# f280015x_adc_regs register map
Vendor: Texas Instruments
Peripheral module from a debugger description file (folder C2000).
Address unit: 16 bits
Registers are 16-bit, read-write, no defined reset value unless marked. A register's access mark holds for its fields unless they carry their own. Offsets are as the file gives them; lines under a group give offsets from that group; [hi:lo] are bit positions; {n}, {i} and the like mark numbered series; 'fields as' and 'values as' point back to an identical list; <NAME> marks a mode.

## ADC_REGS — ADC Registers
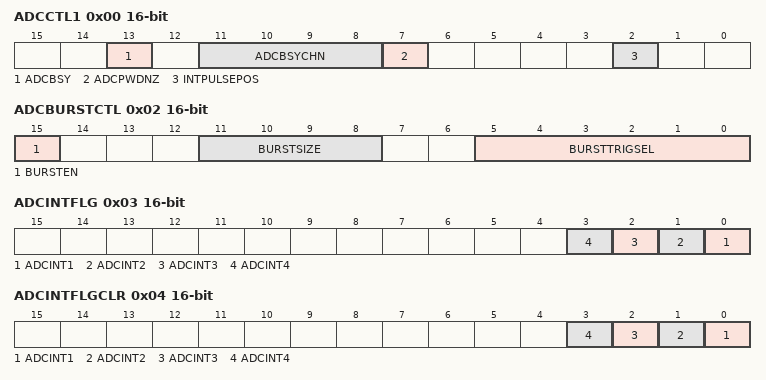
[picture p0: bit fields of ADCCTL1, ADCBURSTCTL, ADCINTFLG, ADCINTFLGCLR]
0x00 ADCCTL1 access per field — ADC Control 1 Register
  [13] ADCBSY ro — ADC Busy
  [11:8] ADCBSYCHN ro — ADC Busy Channel
  [7] ADCPWDNZ rw — ADC Power Down
  [2] INTPULSEPOS rw — ADC Interrupt Pulse Position
0x01 ADCCTL2 — ADC Control 2 Register
  [3:0] PRESCALE — ADC Clock Prescaler
0x02 ADCBURSTCTL — ADC Burst Control Register
  [15] BURSTEN — SOC Burst Mode Enable
  [11:8] BURSTSIZE — SOC Burst Size Select
  [5:0] BURSTTRIGSEL — SOC Burst Trigger Source Select
0x03 ADCINTFLG ro — ADC Interrupt Flag Register
  [n-1] ADCINT{n} (n=1..4) — ADC Interrupt {n} Flag
0x04 ADCINTFLGCLR — ADC Interrupt Flag Clear Register
  [n-1] ADCINT{n} (n=1..4) — ADC Interrupt {n} Flag Clear
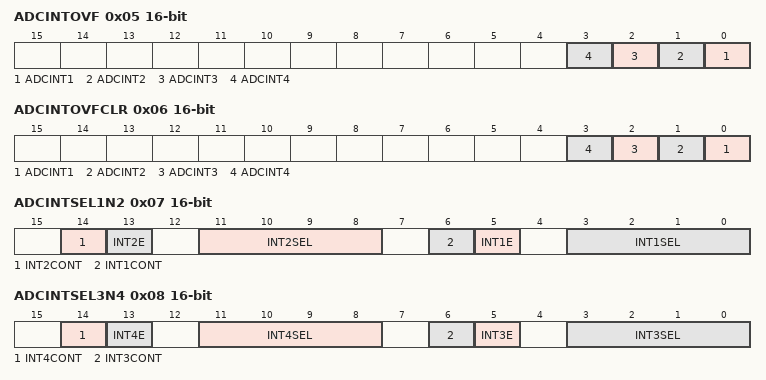
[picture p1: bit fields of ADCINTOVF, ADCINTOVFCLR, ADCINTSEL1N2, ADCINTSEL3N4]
0x05 ADCINTOVF ro — ADC Interrupt Overflow Register
  [n-1] ADCINT{n} (n=1..4) — ADC Interrupt {n} Overflow Flags
0x06 ADCINTOVFCLR — ADC Interrupt Overflow Clear Register
  [n-1] ADCINT{n} (n=1..4) — ADC Interrupt {n} Overflow Clear Bits
0x07 ADCINTSEL1N2 — ADC Interrupt 1 and 2 Selection Register
  [14] INT2CONT — ADCINT2 Continue to Interrupt Mode
  [13] INT2E — ADCINT2 Interrupt Enable
  [11:8] INT2SEL — ADCINT2 EOC Source Select
  [6] INT1CONT — ADCINT1 Continue to Interrupt Mode
  [5] INT1E — ADCINT1 Interrupt Enable
  [3:0] INT1SEL — ADCINT1 EOC Source Select
0x08 ADCINTSEL3N4 — ADC Interrupt 3 and 4 Selection Register
  [14] INT4CONT — ADCINT4 Continue to Interrupt Mode
  [13] INT4E — ADCINT4 Interrupt Enable
  [11:8] INT4SEL — ADCINT4 EOC Source Select
  [6] INT3CONT — ADCINT3 Continue to Interrupt Mode
  [5] INT3E — ADCINT3 Interrupt Enable
  [3:0] INT3SEL — ADCINT3 EOC Source Select
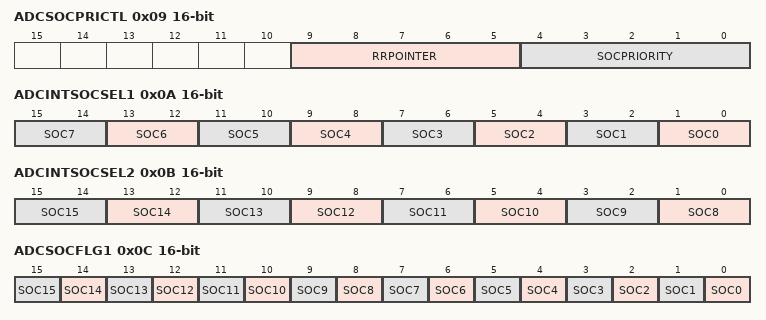
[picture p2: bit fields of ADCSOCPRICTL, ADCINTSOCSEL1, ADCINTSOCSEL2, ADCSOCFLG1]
0x09 ADCSOCPRICTL access per field — ADC SOC Priority Control Register
  [9:5] RRPOINTER ro — Round Robin Pointer
  [4:0] SOCPRIORITY rw
0x0A ADCINTSOCSEL1 — ADC Interrupt SOC Selection 1 Register
  [2n+1:2n] SOC{n} (n=0..7) — SOC{n} ADC Interrupt Trigger Select
0x0B ADCINTSOCSEL2 — ADC Interrupt SOC Selection 2 Register
  [2n-15:2n-16] SOC{n} (n=8..15) — SOC{n} ADC Interrupt Trigger Select
0x0C ADCSOCFLG1 ro — ADC SOC Flag 1 Register
  [n] SOC{n} (n=0..15) — SOC{n} Start of Conversion Flag
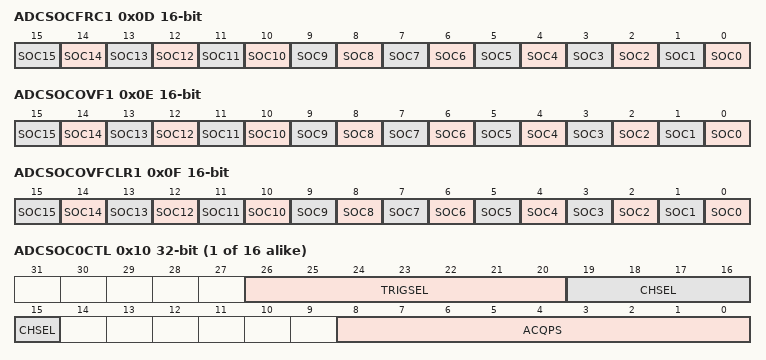
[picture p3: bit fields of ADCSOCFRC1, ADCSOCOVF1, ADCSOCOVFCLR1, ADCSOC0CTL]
0x0D ADCSOCFRC1 — ADC SOC Force 1 Register
  [n] SOC{n} (n=0..15) — SOC{n} Force Start of Conversion Bit
0x0E ADCSOCOVF1 ro — ADC SOC Overflow 1 Register
  [n] SOC{n} (n=0..15) — SOC{n} Start of Conversion Overflow Flag
0x0F ADCSOCOVFCLR1 — ADC SOC Overflow Clear 1 Register
  [n] SOC{n} (n=0..15) — SOC{n} Clear Start of Conversion Overflow Bit
{0x10+2i} ADCSOC{i}CTL 32-bit (i=0..15) — ADC SOC{i} Control Register
  [26:20] TRIGSEL — SOC{i} Trigger Source Select
  [19:15] CHSEL — SOC{i} Channel Select
  [8:0] ACQPS — SOC{i} Acquisition Prescale
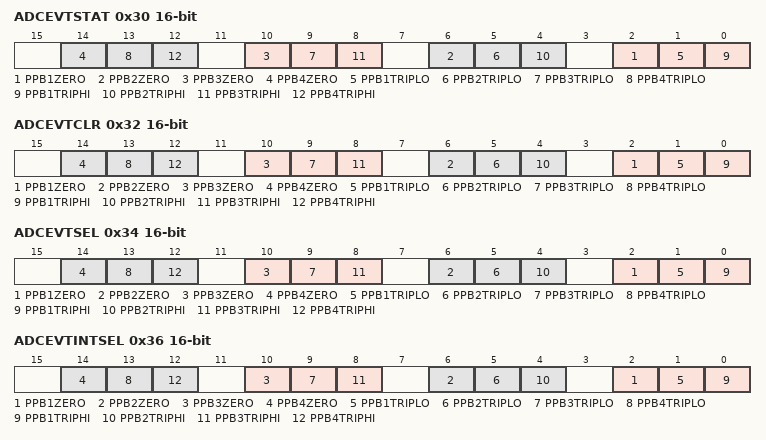
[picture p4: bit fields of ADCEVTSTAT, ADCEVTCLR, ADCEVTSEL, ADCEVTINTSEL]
0x30 ADCEVTSTAT ro — ADC Event Status Register
  [4n-2] PPB{n}ZERO (n=1..4) — Post Processing Block {n} Zero Crossing Flag
  [4n-3] PPB{n}TRIPLO (n=1..4) — Post Processing Block {n} Trip Low Flag
  [4n-4] PPB{n}TRIPHI (n=1..4) — Post Processing Block {n} Trip High Flag
0x32 ADCEVTCLR — ADC Event Clear Register
  [4n-2] PPB{n}ZERO (n=1..4) — Post Processing Block {n} Zero Crossing Clear
  [4n-3] PPB{n}TRIPLO (n=1..4) — Post Processing Block {n} Trip Low Clear
  [4n-4] PPB{n}TRIPHI (n=1..4) — Post Processing Block {n} Trip High Clear
0x34 ADCEVTSEL — ADC Event Selection Register
  [4n-2] PPB{n}ZERO (n=1..4) — Post Processing Block {n} Zero Crossing Event Enable
  [4n-3] PPB{n}TRIPLO (n=1..4) — Post Processing Block {n} Trip Low Event Enable
  [4n-4] PPB{n}TRIPHI (n=1..4) — Post Processing Block {n} Trip High Event Enable
0x36 ADCEVTINTSEL — ADC Event Interrupt Selection Register
  [4n-2] PPB{n}ZERO (n=1..4) — Post Processing Block {n} Zero Crossing Interrupt Enable
  [4n-3] PPB{n}TRIPLO (n=1..4) — Post Processing Block {n} Trip Low Interrupt Enable
  [4n-4] PPB{n}TRIPHI (n=1..4) — Post Processing Block {n} Trip High Interrupt Enable
0x38 ADCOSDETECT — ADC Open and Shorts Detect Register
  [2:0] DETECTCFG — ADC Opens and Shorts Detect Configuration
0x39 ADCCOUNTER ro
  [11:0] FREECOUNT — ADC Free Running Counter Value
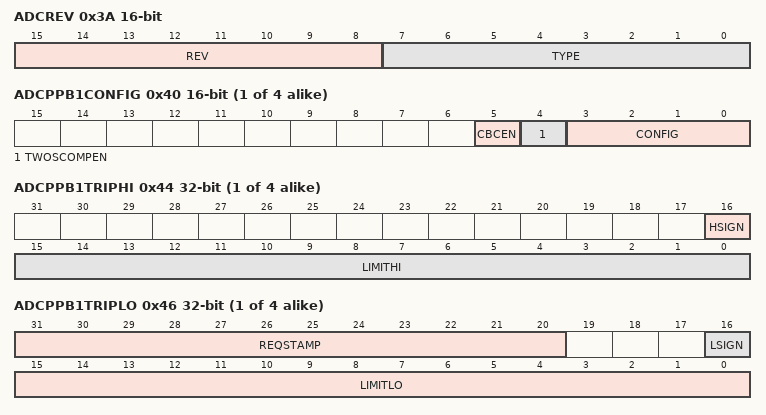
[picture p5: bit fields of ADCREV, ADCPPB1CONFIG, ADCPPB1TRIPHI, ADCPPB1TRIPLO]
0x3A ADCREV ro — ADC Revision Register
  [15:8] REV — ADC Revision
  [7:0] TYPE — ADC Type
0x3B ADCOFFTRIM — ADC Offset Trim Register
  [7:0] OFFTRIM — ADC Offset Trim
{0x38+8i} ADCPPB{i}CONFIG (i=1..4)
  [5] CBCEN — Cycle By Cycle Enable
  [4] TWOSCOMPEN — ADC Post Processing Block {i} Two's Complement Enable
  [3:0] CONFIG — ADC Post Processing Block {i} Configuration
{0x39+8i} ADCPPB{i}STAMP ro (i=1..4) — ADC PPB{i} Sample Delay Time Stamp Register
  [11:0] DLYSTAMP — ADC Post Processing Block {i} Delay Time Stamp
{0x3A+8i} ADCPPB{i}OFFCAL (i=1..4) — ADC PPB{i} Offset Calibration Register
  [9:0] OFFCAL — ADC Post Processing Block Offset Correction
{0x3B+8i} ADCPPB{i}OFFREF (i=1..4) — ADC PPB{i} Offset Reference Register
  [15:0] OFFREF — ADC Post Processing Block {i} Offset Reference
{0x3C+8i} ADCPPB{i}TRIPHI 32-bit (i=1..4) — ADC PPB{i} Trip High Register
  [16] HSIGN — High Limit Sign Bit
  [15:0] LIMITHI — ADC Post Processing Block {i} Trip High Limit
{0x3E+8i} ADCPPB{i}TRIPLO 32-bit access per field (i=1..4) — ADC PPB{i} Trip Low/Trigger Time Stamp Register
  [31:20] REQSTAMP ro — ADC Post Processing Block {i} Request Time Stamp
  [16] LSIGN rw — Low Limit Sign Bit
  [15:0] LIMITLO rw — ADC Post Processing Block {i} Trip Low Limit
0x6F ADCINTCYCLE — ADC Early Interrupt Generation Cycle
  [15:0] DELAY — Delay from ADCSOC fall edge to early interrupt generation.
0x72 ADCINLTRIM2 32-bit — ADC Linearity Trim 2 Register
  [31:0] INLTRIM63TO32 — ADC Linearity Trim Bits 63-32
0x74 ADCINLTRIM3 32-bit — ADC Linearity Trim 3 Register
  [31:0] INLTRIM95TO64 — ADC Linearity Trim Bits 95-64
